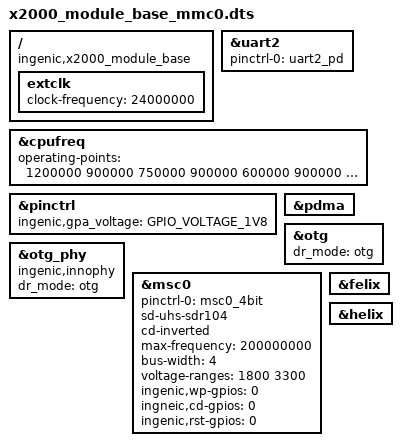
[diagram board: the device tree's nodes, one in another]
/dts-v1/;

#include <dt-bindings/input/input.h>
#include "x2000-v12.dtsi"
#include <dt-bindings/interrupt-controller/irq.h>
#include <generated/autoconf.h>

/ {
	compatible = "ingenic,x2000_module_base", "ingenic,x2000-v12";
};

&uart2 {
	status = "okay";
	pinctrl-names = "default";
	pinctrl-0 = <&uart2_pd>;
};

&cpufreq {
	status = "okay";
	operating-points = <
		/*KHZ uV */
		1200000	900000
		750000	900000
		600000	900000
		500000	900000
		400000	900000
		375000	900000
		300000	900000
		200000	900000
			>;

};

&pinctrl {
	ingenic,gpa_voltage = <GPIO_VOLTAGE_1V8>;
};

&pdma {
	status = "okay";
};

&otg {
	// g-use-dma;
	dr_mode = "otg";
	status = "okay";
};

&otg_phy {
	dr_mode = "otg";
	compatible = "ingenic,innophy", "syscon";
	status = "okay";
};

&msc0 {
	status = "okay";
	pinctrl-names ="default";
	pinctrl-0 = <&msc0_4bit>;
	/*mmc-hs200-1_8v;*/
	/* cap-mmc-highspeed; */
	sd-uhs-sdr104;
	cd-inverted;
	max-frequency = <200000000>;
	bus-width = <4>;
	voltage-ranges = <1800 3300>;

	/* special property */
	ingenic,wp-gpios = <0>;
	ingneic,cd-gpios = <0>;
	ingenic,rst-gpios = <0>;
};

&felix {
	status = "okay";
};

&helix {
	status = "okay";
};

/ {

	extclk: extclk {
		clock-frequency = <24000000>;
	};

	};
